# Cortex_M4 register map
Vendor: Arm Ltd.; Series: ARMv7E-M; File version: 1.0.0
CPU: CM4 r0p0, little endian, MPU, FPU, double-precision FPU, DSP, 8 interrupt priority bits
Registers are 32-bit, read-only, reset 0x0 unless marked. A register's access mark holds for its fields unless they carry their own. Offsets are from the block's base; [hi:lo] are bit positions; {n}, {i} and the like mark numbered series.

## SCnSCB — System control registers not in the SCB: the interrupt controller type and the implementation-defined Auxiliary Control Register.
Base 0xE000E000
0x04 ICTR — Interrupt Controller Type Register: how many interrupt lines the NVIC supports, in groups of 32. Read-only.
  [3:0] INTLINESNUM — Number of interrupt lines in groups of 32: the NVIC supports up to 32 x (INTLINESNUM+1) interrupts (0 = 1-32, 1 = 33-64, ...).
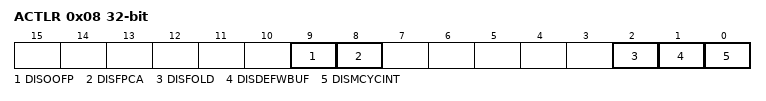
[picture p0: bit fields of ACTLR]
0x08 ACTLR rw — Auxiliary Control Register: implementation-defined controls that disable individual performance features (write buffering, instruction folding, interruptible multi-cycle instructions, FPU behaviours). Usually left at reset; DISDEFWBUF is useful to make imprecise BusFaults precise while debugging.
  [9] DISOOFP — 1 = disable out-of-order completion of floating-point instructions relative to integer instructions (Cortex-M4).
  [8] DISFPCA — 1 = disable the automatic update of CONTROL.FPCA by FP instructions (Cortex-M4/M3 with FPU). Debug use only.
  [2] DISFOLD — 1 = disable IT-block folding (Cortex-M3/M4) / instruction folding (Cortex-M7).
  [1] DISDEFWBUF — 1 = disable the write buffer for default memory map accesses: every BusFault becomes precise, so PRECISERR and BFAR point at the offending store. Costs performance; use while debugging imprecise faults.
  [0] DISMCYCINT — 1 = multi-cycle instructions (LDM, STM, 64-bit loads/stores, MVE) are not interruptible - worst-case interrupt latency rises but becomes deterministic.

## SysTick — 24-bit system timer that counts down from LOAD to 0 on the processor or reference clock and can raise the SysTick exception; the usual RTOS tick source. Banked per security state on ARMv8-M with the Security Extension.
Base 0xE000E010
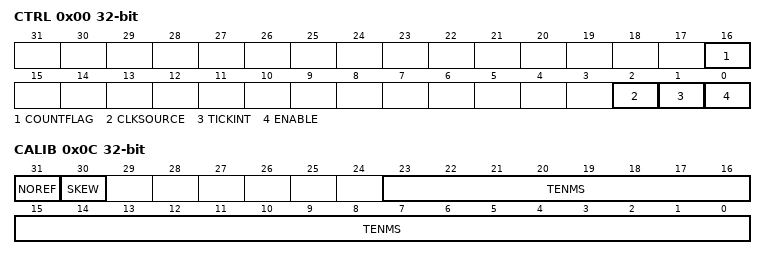
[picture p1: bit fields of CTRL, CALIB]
0x00 CTRL rw — SysTick Control and Status Register: enable, interrupt enable, clock source and the sticky count-to-zero flag.
  [16] COUNTFLAG ro — Reads 1 if the counter reached 0 since the last read of this register. Cleared by reading CTRL or writing VAL.
  [2] CLKSOURCE — Clock source: 0 = external reference clock (implementation defined, e.g. HCLK/8), 1 = processor clock.
    0=External reference clock (implementation defined); 1=Processor clock
  [1] TICKINT — 1 = counting down to 0 sets the SysTick exception pending; 0 = poll COUNTFLAG instead.
  [0] ENABLE — Counter enable: 1 = SysTick counts down from LOAD to 0 and reloads.
0x04 LOAD rw — SysTick Reload Value Register: value loaded into VAL when the counter reaches 0. A period of N clocks needs RELOAD = N-1.
  [23:0] RELOAD — Value loaded into VAL when the counter reaches 0. A period of N clocks needs RELOAD = N-1; 0 is legal but the counter then never fires.
0x08 VAL rw — SysTick Current Value Register: the current count. Any write clears it to 0 and clears CTRL.COUNTFLAG; the next reload comes from LOAD.
  [23:0] CURRENT — Current counter value. Any write clears the field to 0 and clears CTRL.COUNTFLAG.
0x0C CALIB — SysTick Calibration Register: implementation-defined reload value for a 10 ms tick and whether a reference clock exists.
  [31] NOREF — 1 = no separate reference clock: CLKSOURCE reads 1 and cannot be cleared.
  [30] SKEW — 1 = TENMS is not exact (a 10 ms tick cannot be produced exactly).
  [23:0] TENMS — Reload value for a 10 ms period with the reference clock, or 0 if unknown. Implementation defined.

## NVIC — Nested Vectored Interrupt Controller: enable, pending, active and priority registers for the external interrupts (IRQ0 = exception 16) and the software trigger register. Bit k of register n refers to IRQ 32n+k.
Base 0xE000E100
{0x0+4i} ISER{i} (i=0..7) rw — Interrupt Set-Enable Register n (IRQ 32n..32n+31): write 1 to enable an interrupt, 0 has no effect; reads the enable state.
  [31:0] SETENA — Bit k: write 1 to enable IRQ 32n+k; reads 1 if enabled. Writing 0 has no effect.
{0x80+4i} ICER{i} (i=0..7) rw — Interrupt Clear-Enable Register n (IRQ 32n..32n+31): write 1 to disable an interrupt, 0 has no effect; reads the enable state.
  [31:0] CLRENA — Bit k: write 1 to disable IRQ 32n+k; reads 1 if enabled. Writing 0 has no effect.
{0x100+4i} ISPR{i} (i=0..7) rw — Interrupt Set-Pending Register n (IRQ 32n..32n+31): write 1 to set an interrupt pending; reads the pending state.
  [31:0] SETPEND — Bit k: write 1 to set IRQ 32n+k pending; reads 1 if pending.
{0x180+4i} ICPR{i} (i=0..7) rw — Interrupt Clear-Pending Register n (IRQ 32n..32n+31): write 1 to clear a pending interrupt; reads the pending state.
  [31:0] CLRPEND — Bit k: write 1 to clear IRQ 32n+k pending; reads 1 if pending.
{0x200+4i} IABR{i} (i=0..7) — Interrupt Active Bit Register n (IRQ 32n..32n+31): 1 = the interrupt handler is active (executing or preempted). Read-only.
  [31:0] ACTIVE — Bit k: 1 = the handler of IRQ 32n+k is active.
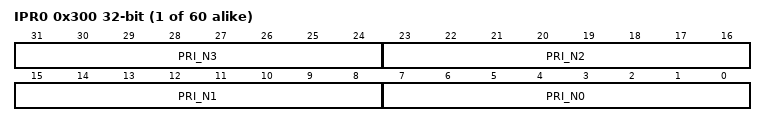
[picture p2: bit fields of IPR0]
{0x300+4i} IPR{i} (i=0..59) rw — Interrupt Priority Register n: one byte per interrupt, IRQ 4n+0 in bits [7:0] up to IRQ 4n+3 in [31:24]. Lower value = higher priority; only the top nvicPrioBits of each byte are implemented (ARMv6-M: 2, typical ARMv7-M: 3-4).
  [8n+7:8n] PRI_N{n} (n=0..3) — Priority of interrupt 4n+{n}. Only the top nvicPrioBits (implementation defined, 2 to 8) are implemented; the rest read as zero.
0xE00 STIR wo — Software Trigger Interrupt Register: writing an interrupt number sets that interrupt pending (like ISPR). Unprivileged writes need CCR.USERSETMPEND.
  [8:0] INTID — Interrupt number to set pending (0 = IRQ0, i.e. exception 16). Unprivileged writes are allowed when CCR.USERSETMPEND is 1.

## Notices in the file
Copyright 2026 Arm Limited. Licensed under the Apache License, Version 2.0.
Copyright 2026 Arm Limited. Licensed under the Apache License, Version 2.0 (the "License");
you may not use this file except in compliance with the License. You may obtain a copy of the License at
https://www.apache.org/licenses/LICENSE-2.0
Unless required by applicable law or agreed to in writing, software
distributed under the License is distributed on an "AS IS" BASIS, WITHOUT WARRANTIES OR CONDITIONS OF ANY KIND,
either express or implied. See the License for the specific language governing permissions and limitations under the License.
